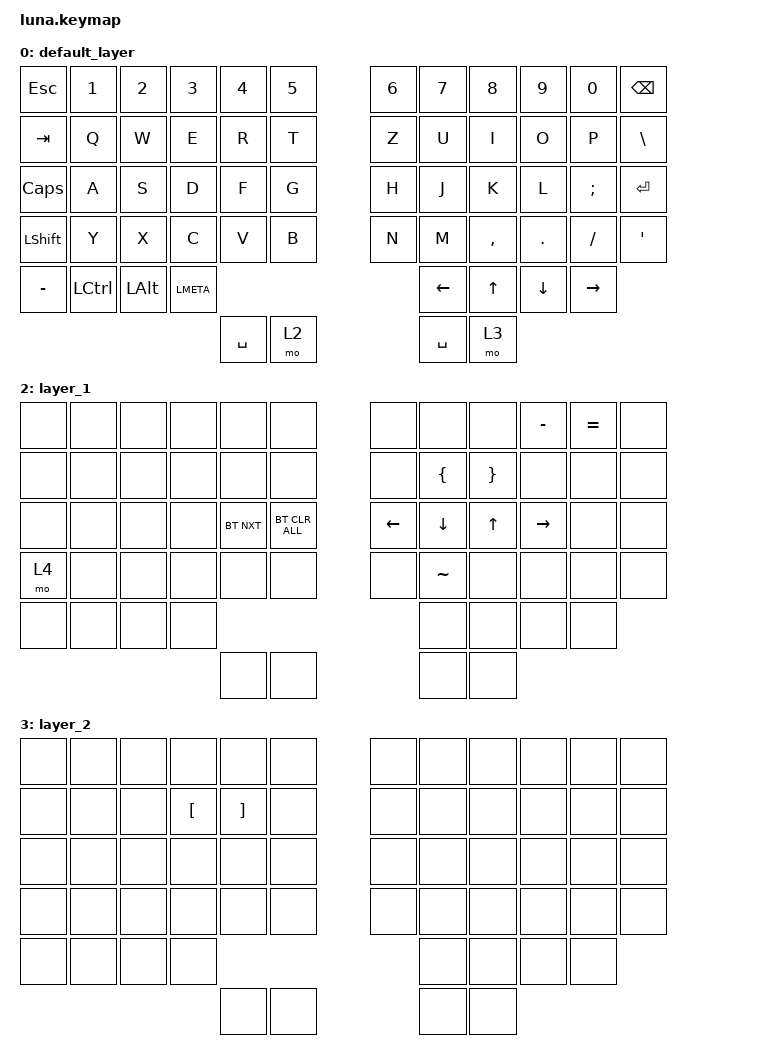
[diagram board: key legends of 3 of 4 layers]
#include <behaviors.dtsi>
#include <dt-bindings/zmk/keys.h>
#include <dt-bindings/zmk/bt.h>
#include "keys_de.h"

/ {
        keymap {
                compatible = "zmk,keymap";

                default_layer {
                        bindings = <
   &kp ESC    &kp N1    &kp N2    &kp N3     &kp N4     &kp N5               &kp N6     &kp N7  &kp N8     &kp N9    &kp N0    &kp BSPC
   &kp TAB    &kp Q     &kp W     &kp E      &kp R      &kp T                &kp Z      &kp U   &kp I      &kp O     &kp P     &kp BSLH
   &kp CAPS   &kp A     &kp S     &kp D      &kp F      &kp G                &kp H      &kp J   &kp K      &kp L     &kp SEMI  &kp RET
   &kp LSHFT  &kp Y     &kp X     &kp C      &kp V      &kp B                &kp N      &kp M   &kp COMMA  &kp DOT   &kp FSLH  &kp APOS
   &kp MINUS  &kp LCTRL &kp LALT  &kp LMETA                                             &kp LEFT   &kp UP  &kp DOWN  &kp RIGHT
                                        &kp SPACE  &mo 2                             &kp SPACE &mo 3
                        >;
                };
                lower_layer {
                        bindings = <
   &none    &bt BT_SEL 0   &bt BT_SEL 1   &bt BT_SEL 2   &bt BT_SEL 3   &bt BT_SEL 4           &none    &none    &none   &none   &none  &bt BT_CLR
   &none    &none         &none         &none         &none         &none                 &none    &none    &none   &none   &none  &none
   &none    &none         &none         &kp LPAR       &kp RPAR       &none                 &none    &kp LBKT  &kp RBKT &kp MINUS   &kp EQUAL  &none
   &none    &none         &none         &none         &none         &none                 &none    &none    &none   &none   &none  &none
                        >;
                };
                layer_1 {
                        bindings = <
   &none    &none         &none         &none         &none         &none                 &none    &none      &none       &kp MINUS        &kp EQUAL      &none
   &none    &none         &none         &none         &none         &none                 &none &kp LBRC    &kp RBRC            &none        &none      &none
   &none    &none         &none         &none         &bt BT_NXT         &bt BT_CLR_ALL                 &kp LEFT    &kp DOWN      &kp UP       &kp RIGHT        &none      &none
   &mo 4    &none         &none         &none         &none         &none                 &none    &kp TILDE      &none       &none        &none      &none
   &none    &none         &none         &none                                                                 &none       &none        &none      &none
                                                                &none    &none         &none      &none
                        >;
                };
                layer_2 {
                        bindings = <
   &none    &none         &none         &none         &none         &none                 &none    &none      &none       &none        &none      &none
   &none    &none         &none         &kp LBKT         &kp RBKT &none                &none    &none      &none       &none        &none      &none
   &none    &none         &none         &none         &none         &none                 &none    &none      &none       &none        &none      &none
   &none    &none         &none         &none         &none         &none                 &none    &none      &none       &none        &none      &none
   &none    &none         &none         &none                                                                 &none       &none        &none      &none
                                                                &none    &none         &none      &none
                        >;
                };

        };
};
